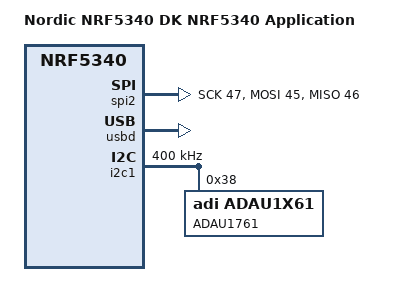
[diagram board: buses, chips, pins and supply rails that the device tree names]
/*
 * Copyright (c) 2020 Nordic Semiconductor ASA
 *
 * SPDX-License-Identifier: Apache-2.0
 */

/dts-v1/;
#include <nordic/nrf5340_cpuapp_qkaa.dtsi>
#include "nrf5340_cpuapp_common.dts"

/ {
	model = "Nordic NRF5340 DK NRF5340 Application";
	compatible = "nordic,nrf5340-dk-nrf5340-cpuapp";

	chosen {
		zephyr,sram = &sram0_image;
		zephyr,flash = &flash0;
		zephyr,code-partition = &slot0_partition;
		zephyr,sram-secure-partition = &sram0_s;
		zephyr,sram-non-secure-partition = &sram0_ns;
	};
};

&spi2 {
	compatible = "nordic,nrf-spim";
	status = "okay";
	sck-pin = <47>;
	miso-pin = <46>;
	mosi-pin = <45>;
};

&usbd {
	compatible = "nordic,nrf-usbd";
	status = "okay";
};

&i2c1 {
	status = "okay";
	clock-frequency = <I2C_BITRATE_FAST>;

	codec0: adau1361@38 {
		compatible = "adi,adau1x61";
		reg = <0x38>;
		label = "ADAU1761";
	};
};
